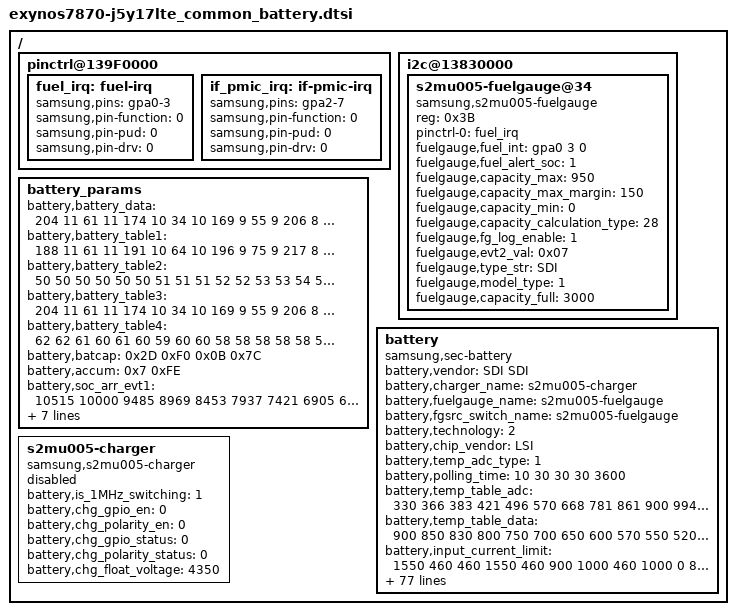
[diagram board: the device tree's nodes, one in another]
/*
 * SAMSUNG UNIVERSAL5433 board device tree source
 *
 * Copyright (c) 2013 Samsung Electronics Co., Ltd.
 *		http://www.samsung.com
 *
 * This program is free software; you can redistribute it and/or modify
 * it under the terms of the GNU General Public License version 2 as
 * published by the Free Software Foundation.
*/

/ {
	pinctrl@139F0000 {
		fuel_irq: fuel-irq {
			samsung,pins = "gpa0-3";
			samsung,pin-function = <0>;
			samsung,pin-pud = <0>;
			samsung,pin-drv = <0>;
		};
	};

	pinctrl@139F0000 {
		if_pmic_irq: if-pmic-irq {
			samsung,pins = "gpa2-7";
			samsung,pin-function = <0>;
			samsung,pin-pud = <0>;
			samsung,pin-drv = <0>;
		};
	};

	i2c@13830000 {
		status = "okay";
		s2mu005-fuelgauge@34 {
			compatible = "samsung,s2mu005-fuelgauge";
			reg = <0x3B>;
			pinctrl-names = "default";
			pinctrl-0 = <&fuel_irq>;
			fuelgauge,fuel_int = <&gpa0 3 0>;
			fuelgauge,fuel_alert_soc = <1>;
			fuelgauge,capacity_max = <950>;
			fuelgauge,capacity_max_margin = <150>;
			fuelgauge,capacity_min = <0>;
			fuelgauge,capacity_calculation_type = <28>;
			fuelgauge,fg_log_enable = <1>;
			fuelgauge,evt2_val = <0x07>;
			fuelgauge,type_str = "SDI";
			fuelgauge,model_type = <1>;
			fuelgauge,capacity_full = <3000>;
		};
	};

	battery_params {
		battery,battery_data = 
			<
				/***** battery data for 4.35 *****/
				/* battery,battery_table3 */
				204 11 61 11 174 10 34 10 169 9
				55 9 206 8 107 8 230 7 166 7
				77 7 234 6 174 6 130 6 95 6
				67 6 36 6 253 5 197 5 147 5
				42 5 168 1 216 8 106 8 252 7
				142 7 32 7 178 6 68 6 213 5
				103 5 249 4 139 4 29 4 175 3
				65 3 211 2 101 2 247 1 137 1
				27 1 172 0 62 0 208 15

				/* battery,battery_table4 */
				62 62 61 60 61 60 59 60 60 58
				58 58 58 58 58 58 59 60 62 64
				76 148

				/* battery,batcap */
				0x2D 0xF0 0x0B 0x7C /* [0x0F] [0x0E] [0x11] [0x10] */
				/* battery,accum */ 
				0xFE 0x07 /* [0x44] [0x45] */

				/* battery,soc_arr_val */
				11055 10517 9980 9442 8905 8367 7830 7292 6755 6217
				5679 5142 4605 4067 3529 2992 2454 1917 1380 842
				304 (-233)

				/* battery,ocv_arr_val */
				44748 44050 43352 42664 42077 41519 41006 40523 39872 39563
				39127 38645 38349 38135 37966 37827 37676 37485 37211 36970
				36454 32069


				/***** battery data for 4.33 *****/
				/* battery,battery_table3 */
				80 11 211 10 85 10 216 9 99 9
				244 8 141 8 41 8 212 7 133 7
				22 7 207 6 158 6 120 6 89 6
				63 6 29 6 243 5 196 5 136 5
				105 5 199 2 219 8 110 8 0 8
				146 7 37 7 183 6 73 6 220 5
				110 5 0 5 147 4 37 4 183 3
				74 3 220 2 111 2 1 2 147 1
				38 1 184 0 74 0 221 15

				/* battery,battery_table4 */
				53 53 52 52 52 53 53 53 52 52
				53 53 54 54 53 54 54 55 56 61
				75 133

				/* battery,batcap */
				0x2C 0x10 0x0B 0x04 /* [0x0F] [0x0E] [0x11] [0x10] */
				/* battery,accum */
				0xFE 0x07 /* [0x44] [0x45] */

				/* battery,soc_arr_val */
				11070 10535 10000 9465 8929 8394 7859 7323 6788 6252
				5717 5182 4646 4111 3576 3040 2505 1970 1434 898
				363 (-173)
				/* battery,ocv_arr_val */
				44143 43530 42917 42304 41734 41194 40687 40199 39787 39399
				38859 38509 38272 38085 37936 37808 37642 37439 37205 36913
				36763 33474

				/***** battery data for 4.31 *****/
				/* battery,battery_table3 */
				40 11 172 10 48 10 181 9 66 9
				213 8 114 8 14 8 190 7 105 7
				252 6 191 6 146 6 110 6 81 6
				56 6 17 6 234 5 177 5 133 5
				9 5 92 1 223 8 112 8 0 8
				144 7 33 7 177 6 65 6 210 5
				98 5 242 4 131 4 19 4 163 3
				52 3 196 2 84 2 229 1 117 1
				5 1 149 0 38 0 201 15

				/* battery,battery_table4 */
				51 51 51 51 51 52 52 52 53 52
				52 53 53 54 54 55 55 56 56 58
				62 151

				/* battery,batcap */                                  
				0x2B 0x48 0x0A 0xD2 /* [0x0F] [0x0E] [0x11] [0x10] */ 
				/* battery,accum */
				0xFE 0x07 /* [0x44] [0x45] */

				/* battery,soc_arr_val */
				11090 10545 10000 9455 8909 8364 7819 7274 6728 6183
				5638 5092 4547 4002 3457 2911 2366 1821 1275 730
				185 (-270)
				/* battery,ocv_arr_val */
				43944 43340 42736 42132 41573 41042 40556 40069 39680 39264
				38730 38431 38211 38036 37896 37774 37582 37392 37114 36900
				36295 31701


				/***** battery data for 4.29 *****/
				/* batterybattery_table3 */
				254 10 132 10 10 10 144 9 30 9
				179 8 81 8 243 7 166 7 67 7
				230 6 176 6 134 6 101 6 74 6
				46 6 4 6 219 5 153 5 130 5
				97 4 70 1 226 8 113 8 0 8
				143 7 30 7 173 6 60 6 203 5
				90 5 233 4 120 4 7 4 150 3
				37 3 180 2 67 2 211 1 97 1
				240 0 127 0 14 0 210 15

				/* batterybattery_table4 */
				52 52 52 51 51 52 52 52 53 52
				52 52 53 54 54 55 55 56 57 60
				68 135

				/* battery,batcap */                                  
				0x2A 0xA8 0x0A 0xAA /* [0x0F] [0x0E] [0x11] [0x10] */ 
				/* battery,accum */
				0xFE 0x07 /* [0x44] [0x45] */

				/* battery,soc_arr_val */
				11104 10552 10000 9448 8897 8345 7794 7242 6690 6139
				5587 5036 4484 3932 3381 2829 2278 1726 1174 622
				70 (-224)

				/* battery,ocv_arr_val */
				43742 43145 42548 41951 41397 40875 40395 39938 39560 39077
				38622 38358 38154 37991 37861 37724 37518 37319 36996 36884
				35474 31590

				/***** battery data for 4.24 *****/
				/* battery,battery_table3 */
				9 11 147 10 29 10 167 9 50 9
				196 8 97 8 0 8 177 7 88 7
				240 6 183 6 140 6 105 6 78 6
				51 6 9 6 227 5 165 5 132 5
				183 4 67 1 100 9 238 8 119 8
				0 8 137 7 19 7 156 6 37 6
				174 5 56 5 193 4 74 4 212 3
				93 3 230 2 111 2 249 1 130 1
				11 1 148 0 30 0 206 15

				/* battery,battery_table4 */
				51 51 51 51 51 51 52 52 52 52
				52 52 53 54 54 55 55 56 57 60
				66 154

				/* battery,batcap */                                  
				0x28 0xA0 0x0A 0x28 /* [0x0F] [0x0E] [0x11] [0x10] */ 
				/* battery,accum */
				0xFE 0x07 /* [0x44] [0x45] */

				/* battery,soc_arr_val */
				11740 11160 10580 10000 9420 8841 8261 7681 7101 6522
				5942 5362 4783 4203 3623 3043 2464 1884 1304 725
				145 (-245)

				/* battery,ocv_arr_val */
				43793 43218 42643 42068 41493 40958 40475 40001 39614 39178
				38671 38394 38182 38014 37881 37750 37546 37358 37056 36896
				35892 31579
			>;
				
			battery,battery_table1 = <188 11 61 11 191 10 64 10 196 9
					75 9 217 8 110 8 13 8 173 7
					66 7 235 6 177 6 132 6 96 6
					67 6 31 6 242 5 164 5 124 5
					23 5 144 1 216 8 105 8 251 7
					141 7 30 7 176 6 65 6 211 5
					101 5 246 4 136 4 25 4 171 3
					60 3 206 2 95 2 241 1 131 1
					20 1 166 0 55 0 201 15>;

			battery,battery_table2 = <50 50 50 50 50 50 51 51 51 52
					52 53 53 54 54 55 55 56 57 59
					63 154>;

			battery,battery_table3 = <204 11 61 11 174 10 34 10 169 9
				55 9 206 8 107 8 230 7 166 7
				77 7 234 6 174 6 130 6 95 6
				67 6 36 6 253 5 197 5 147 5
				42 5 168 1 216 8 106 8 252 7
				142 7 32 7 178 6 68 6 213 5
				103 5 249 4 139 4 29 4 175 3
				65 3 211 2 101 2 247 1 137 1
				27 1 172 0 62 0 208 15>;

			battery,battery_table4 = <62 62 61 60 61 60 59 60 60 58
				58 58 58 58 58 58 59 60 62 64
				76 148>;

			battery,batcap = <0x2D 0xF0 0x0B 0x7C>; /* [0x0F] [0x0E] [0x11] [0x10] */
			battery,accum = <0x7 0xFE>; /* [0x45] [0x44] */

			battery,soc_arr_evt1 = <10515 10000 9485 8969 8453 7937 7421 6905 6389 5873 5358 4842 4326 3810 3294 2778 2263 1747 1231 716 200 (-269)>;
			battery,ocv_arr_evt1 = <44051 43459 42867 42288 41716 41175 40664 40199 39779 39268 38784 38482 38250 38059 37906 37778 37594 37368 36957 36835 36289 31955>;

			battery,soc_arr_evt2 = <11055 10517 9980 9442 8905 8367 7830 7292 6755 6217 5679 5142 4605 4067 3529 2992 2454 1917 1380 842 304 (-233)>;
			battery,ocv_arr_evt2 = <44748 44050 43352 42664 42077 41519 41006 40523 39872 39563 39127 38645 38349 38135 37966 37827 37676 37485 37211 36970 36454 32069>;

			battery,FG_Accumulative_rate_evt2 = <0xFE 0x07>;  /* [0x44] [0x45] */
	};

	battery {
		status = "okay";

		pinctrl-names = "default";

		compatible = "samsung,sec-battery";
		battery,vendor = "SDI SDI";
		battery,charger_name = "s2mu005-charger";
		battery,fuelgauge_name = "s2mu005-fuelgauge";
		battery,fgsrc_switch_name = "s2mu005-fuelgauge";
		battery,technology = <2>; /* POWER_SUPPLY_TECHNOLOGY_LION */

		battery,chip_vendor = "LSI";
		battery,temp_adc_type = <1>; /* SEC_BATTERY_ADC_TYPE_AP */

		battery,polling_time = <10 30 30 30 3600>;

		battery,temp_table_adc = <330 366 383 421 496 570 668 781 861 900 994 1056 1152 1220 1405 1609 
								1820 2028 2246 2444 2652 2818 2914 2977 3040 3117 3152 3213 3279 3416 3531 3630>;

		battery,temp_table_data = <900 850 830 800 750 700 650 600 570 550 520 500 470 450 400 350 
								300 250 200 150 100 70 50 30 20 0 (-10) (-30) (-50) (-100) (-150) (-200)>;

		battery,input_current_limit = <1550 460 460 1550 460 900 1000 460 1000 0 820 820 820 1550 1550 0 0 400 700 1300 300 1000 1550 0 1550 1550 1000 1550 80 1550 1550 1400 1000 1000 820 820 820 820 1550 1550 1550 1550 1550 1550>;
		battery,fast_charging_current = <2100 0 0 2100 460 1200 1000 460 1200 0 1200 1200 1200 1700 2100 0 0 400 700 1300 300 1000 1500 0 2100 2100 1000 2100 80 2100 1000 1400 0 1000 1200 1200 1200 1200 2100 2100 2100 2100 2100 2100>;
		battery,full_check_current_1st = <300 0 0 300 300 300 300 300 300 0 300 300 300 300 300 0 0 300 300 300 300 300 300 0 300 300 300 300 0 300 300 300 0 300 300 300 300 300 300 300 300 300 300 300>;
		battery,full_check_current_2nd = <150 0 0 150 150 150 150 150 150 0 150 150 150 150 150 0 0 150 150 150 150 150 150 0 150 150 150 150 0 150 150 150 0 150 150 150 150 150 150 150 150 150 150 150>;

		battery,wireless_cc_cv = <86>;
		battery,inbat_voltage = <1>;

		battery,inbat_voltage_table_adc = <2844 2815 2786 2756 2729 2697 2677 2646 2616 2586
						2557 2526 2498 2468 2440 2417 2387 2358 2327 2300
						2269 2240 2211 2183 2158 2128 2100 2070>;
		battery,inbat_voltage_table_data = <4350 4300 4250 4200 4150 4100 4050 4000 3950 3900
						3850 3800 3750 3700 3650 3600 3550 3500 3450 3400
						3350 3300 3250 3200 3150 3100 3050 3000>;

		battery,adc_check_count = <5>;

		battery,cable_check_type = <4>; /* SEC_BATTERY_CABLE_CHECK_PSY */
		battery,cable_source_type = <1>; /* SEC_BATTERY_CABLE_SOURCE_EXTERNAL */
		battery,polling_type = <1>; /* SEC_BATTERY_MONITOR_ALARM */
		battery,monitor_initial_count = <0>;

		battery,battery_check_type = <5>; /* SEC_BATTERY_CHECK_CHARGER */
		battery,check_count = <0>;

		battery,ovp_uvlo_check_type = <3>; /* SEC_BATTERY_OVP_UVLO_CHGPOLLING */

		battery,check_adc_max = <1440>;
		battery,check_adc_min = <0>;

		battery,thermal_source = <2>; /* SEC_BATTERY_THERMAL_SOURCE_ADC */

		battery,temp_check_type = <2>; /* SEC_BATTERY_TEMP_CHECK_TEMP */
		battery,temp_check_count = <1>;
		battery,temp_highlimit_threshold_normal = <800>;
		battery,temp_highlimit_recovery_normal = <750>;
		battery,temp_high_threshold_normal = <500>;
		battery,temp_high_recovery_normal = <450>;
		battery,temp_low_threshold_normal = <0>;
		battery,temp_low_recovery_normal = <50>;
		battery,temp_highlimit_threshold_lpm = <800>;
		battery,temp_highlimit_recovery_lpm = <750>;
		battery,temp_high_threshold_lpm = <500>;
		battery,temp_high_recovery_lpm = <450>;
		battery,temp_low_threshold_lpm = <0>;
		battery,temp_low_recovery_lpm = <50>;

		battery,full_check_type = <2>; /* SEC_BATTERY_FULLCHARGED_FG_CURRENT */
		battery,full_check_type_2nd = <2>; /* SEC_BATTERY_FULLCHARGED_FG_CURRENT */
		battery,full_check_count = <1>;
		battery,chg_gpio_full_check = <0>;
		battery,chg_polarity_full_check = <1>;

		/* SEC_BATTERY_FULL_CONDITION_SOC |
		   SEC_BATTERY_FULL_CONDITION_NOTIMEFULL |
		   SEC_BATTERY_FULL_CONDITION_VCELL */
		battery,full_condition_type = <15>;
		battery,full_condition_soc = <93>;
		battery,full_condition_vcell = <4290>;
		battery,battery_full_capacity = <3000>;

		battery,recharge_check_count = <2>;
		battery,recharge_condition_type = <4>; /* SEC_BATTERY_RECHARGE_CONDITION_VCELL */
		battery,recharge_condition_soc = <98>;
		battery,recharge_condition_vcell = <4250>;
		
		battery,expired_time = <12000>;
		battery,recharginig_expired_time = <5400>;
		battery,standard_curr = <2100>;

		battery,charging_total_time = <21600>;
		battery,recharging_total_time = <5400>;
		battery,charging_reset_time = <0>;

		battery,chg_float_voltage = <4350>;


		battery,swelling_high_temp_block = <410>;
		battery,swelling_high_temp_recov = <390>;
		battery,swelling_low_temp_2step_mode = <1>;
		battery,swelling_low_temp_block_1st = <150>;
		battery,swelling_low_temp_recov_1st = <200>;
		battery,swelling_low_temp_block_2nd = <50>;
		battery,swelling_low_temp_recov_2nd = <100>;
		battery,swelling_low_temp_current = <900>;
		battery,swelling_low_temp_topoff = <150>;
		battery,swelling_high_temp_current = <1350>;
		battery,swelling_high_temp_topoff = <150>;
		battery,swelling_drop_float_voltage = <4150>;
		battery,swelling_high_rechg_voltage = <4000>;
		battery,swelling_low_rechg_voltage = <4000>;

		battery,siop_input_limit_current = <1550>;
		battery,siop_charging_limit_current = <1000>;

		/* cycle, chg_float_voltage, recharge_condition_vcell, full_condition_vcell, full_condition_soc */
		battery,age_data = <0 4350 4250 4250 92	/*4.35*/
				200 4330 4230 4230 91	/*4.33*/
				250 4310 4210 4210 89	/*4.31*/
				300 4290 4190 4190 87	/*4.29*/
				1000 4240 4140 4140 83	/*4.24*/
				>;

		io-channels = <&exynos_adc 1>,<&exynos_adc 3>;
		io-channel-names = "adc-temp","adc-in-bat";
		#io-channel-cells = <1>;
		io-channel-ranges;
	};

	s2mu005-charger {
		status = "disable";
		compatible = "samsung,s2mu005-charger";
		battery,is_1MHz_switching = <1>;
		battery,chg_gpio_en = <0>;
		battery,chg_polarity_en = <0>;
		battery,chg_gpio_status = <0>;
		battery,chg_polarity_status = <0>;
		battery,chg_float_voltage = <4350>;
	};
};
